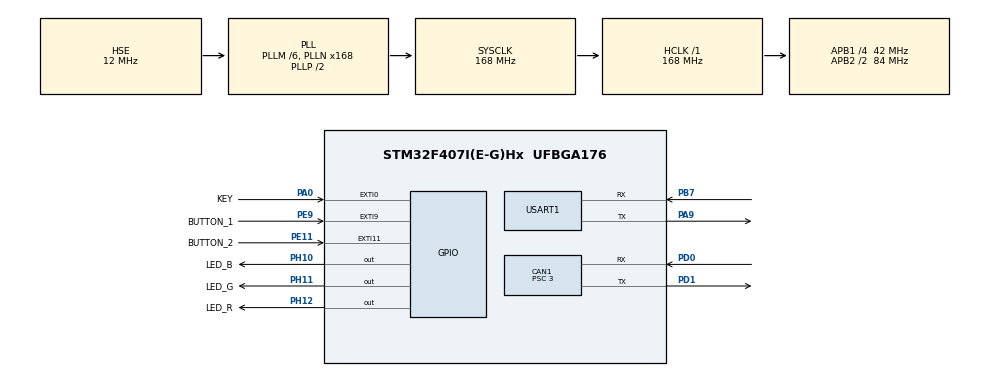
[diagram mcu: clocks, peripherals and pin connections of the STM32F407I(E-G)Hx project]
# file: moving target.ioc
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CAN1.BS1=CAN_BS1_9TQ
CAN1.BS2=CAN_BS2_4TQ
CAN1.CalculateBaudRate=1000000
CAN1.CalculateTimeBit=1000
CAN1.CalculateTimeQuantum=71.42857142857143
CAN1.Prescaler=3
Dma.Request0=USART1_RX
Dma.Request1=USART1_TX
Dma.USART1_RX.0.Direction=DMA_PERIPH_TO_MEMORY
Dma.USART1_RX.0.FIFOMode=DMA_FIFOMODE_DISABLE
Dma.USART1_RX.0.Instance=DMA2_Stream2
Dma.USART1_RX.0.MemDataAlignment=DMA_MDATAALIGN_BYTE
Dma.USART1_RX.0.MemInc=DMA_MINC_ENABLE
Dma.USART1_RX.0.Mode=DMA_NORMAL
Dma.USART1_RX.0.PeriphDataAlignment=DMA_PDATAALIGN_BYTE
Dma.USART1_RX.0.PeriphInc=DMA_PINC_DISABLE
Dma.USART1_RX.0.Priority=DMA_PRIORITY_HIGH
Dma.USART1_TX.1.Direction=DMA_MEMORY_TO_PERIPH
Dma.USART1_TX.1.FIFOMode=DMA_FIFOMODE_DISABLE
Dma.USART1_TX.1.Instance=DMA2_Stream7
Dma.USART1_TX.1.MemDataAlignment=DMA_MDATAALIGN_BYTE
Dma.USART1_TX.1.MemInc=DMA_MINC_ENABLE
Dma.USART1_TX.1.Mode=DMA_NORMAL
Dma.USART1_TX.1.PeriphDataAlignment=DMA_PDATAALIGN_BYTE
Dma.USART1_TX.1.PeriphInc=DMA_PINC_DISABLE
Dma.USART1_TX.1.Priority=DMA_PRIORITY_HIGH
Mcu.Family=STM32F4
Mcu.Name=STM32F407I(E-G)Hx
Mcu.Package=UFBGA176
NVIC.CAN1_RX0_IRQn=true\:0\:0\:false\:false\:true\:true\:true\:true
NVIC.CAN1_TX_IRQn=true\:0\:0\:false\:false\:true\:true\:true\:true
NVIC.DMA2_Stream2_IRQn=true\:0\:0\:false\:false\:true\:false\:true\:true
NVIC.DMA2_Stream7_IRQn=true\:0\:0\:false\:false\:true\:false\:true\:true
NVIC.EXTI0_IRQn=true\:0\:0\:false\:false\:true\:true\:true\:true
NVIC.EXTI15_10_IRQn=true\:1\:0\:true\:false\:true\:true\:true\:true
NVIC.EXTI9_5_IRQn=true\:1\:0\:true\:false\:true\:true\:true\:true
NVIC.PriorityGroup=NVIC_PRIORITYGROUP_4
NVIC.TIM1_BRK_TIM9_IRQn=true\:5\:0\:true\:false\:true\:true\:true\:true
NVIC.TIM1_CC_IRQn=true\:5\:0\:true\:false\:true\:true\:true\:true
NVIC.TIM1_TRG_COM_TIM11_IRQn=true\:5\:0\:true\:false\:true\:true\:true\:true
NVIC.TIM1_UP_TIM10_IRQn=true\:5\:0\:true\:false\:true\:true\:true\:true
NVIC.USART1_IRQn=true\:0\:0\:false\:false\:true\:true\:true\:true
PA0-WKUP.GPIO_Label=KEY
PA0-WKUP.GPIO_ModeDefaultEXTI=GPIO_MODE_IT_FALLING
PA0-WKUP.Signal=GPXTI0
PA13.Mode=Serial_Wire
PA13.Signal=SYS_JTMS-SWDIO
PA14.Mode=Serial_Wire
PA14.Signal=SYS_JTCK-SWCLK
PA9.Mode=Asynchronous
PA9.Signal=USART1_TX
PB7.Mode=Asynchronous
PB7.Signal=USART1_RX
PD0.Mode=CAN_Activate
PD0.Signal=CAN1_RX
PD1.Mode=CAN_Activate
PD1.Signal=CAN1_TX
PE11.GPIO_Label=BUTTON_2
PE11.GPIO_ModeDefaultEXTI=GPIO_MODE_IT_RISING
PE11.GPIO_PuPd=GPIO_PULLDOWN
PE11.Signal=GPXTI11
PE9.GPIO_Label=BUTTON_1
PE9.GPIO_ModeDefaultEXTI=GPIO_MODE_IT_RISING
PE9.GPIO_PuPd=GPIO_PULLDOWN
PE9.Signal=GPXTI9
PH0-OSC_IN.Mode=HSE-External-Oscillator
PH0-OSC_IN.Signal=RCC_OSC_IN
PH1-OSC_OUT.Mode=HSE-External-Oscillator
PH1-OSC_OUT.Signal=RCC_OSC_OUT
PH10.GPIO_Label=LED_B
PH10.Signal=GPIO_Output
PH11.GPIO_Label=LED_G
PH11.Signal=GPIO_Output
PH12.GPIO_Label=LED_R
PH12.Signal=GPIO_Output
ProjectManager.HeapSize=0x200
ProjectManager.StackSize=0x400
ProjectManager.TargetToolchain=CMake
RCC.48MHZClocksFreq_Value=84000000
RCC.AHBFreq_Value=168000000
RCC.APB1CLKDivider=RCC_HCLK_DIV4
RCC.APB1Freq_Value=42000000
RCC.APB1TimFreq_Value=84000000
RCC.APB2CLKDivider=RCC_HCLK_DIV2
RCC.APB2Freq_Value=84000000
RCC.APB2TimFreq_Value=168000000
RCC.CortexFreq_Value=168000000
RCC.HCLKFreq_Value=168000000
RCC.HSE_VALUE=12000000
RCC.HSI_VALUE=16000000
RCC.LSE_VALUE=32768
RCC.PLLM=6
RCC.PLLN=168
RCC.PLLSourceVirtual=RCC_PLLSOURCE_HSE
RCC.SYSCLKFreq_VALUE=168000000
RCC.SYSCLKSource=RCC_SYSCLKSOURCE_PLLCLK
RCC.VCOOutputFreq_Value=336000000
TIM1.Period=1000-1
TIM1.Prescaler=168-1
TIM2.Prescaler=84-1
USART1.VirtualMode=VM_ASYNC
VP_TIM1_VS_ClockSourceINT.Mode=Internal
VP_TIM2_VS_ClockSourceINT.Mode=Internal
board=custom

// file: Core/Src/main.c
/* USER CODE BEGIN Header */
/**
 ******************************************************************************
 * @file           : main.c
 * @brief          : Main program body
 ******************************************************************************
 * @attention
 *
 * Copyright (c) 2024 STMicroelectronics.
 * All rights reserved.
 *
 * This software is licensed under terms that can be found in the LICENSE file
 * in the root directory of this software component.
 * If no LICENSE file comes with this software, it is provided AS-IS.
 *
 ******************************************************************************
 */
/* USER CODE END Header */
#include "main.h"
#include "can.h"
#include "dma.h"
#include "tim.h"
#include "usart.h"
#include "gpio.h"

/* USER CODE BEGIN Includes */

#include "../../../src/entrypoint.hpp"

/* USER CODE END Includes */

void SystemClock_Config(void);

int main(void)
{

  /* MCU Configuration--------------------------------------------------------*/

  /* Reset of all peripherals, Initializes the Flash interface and the Systick. */
  HAL_Init();

  /* Configure the system clock */
  SystemClock_Config();

  /* Initialize all configured peripherals */
  MX_GPIO_Init();
  MX_DMA_Init();
  MX_CAN1_Init();
  MX_USART1_UART_Init();
  MX_TIM1_Init();
  MX_TIM2_Init();
  /* USER CODE BEGIN 2 */

    entrypoint();

  /* USER CODE END 2 */

  /* Infinite loop */
    while (1) {

    }
}

void SystemClock_Config(void)
{
  RCC_OscInitTypeDef RCC_OscInitStruct = {0};
  RCC_ClkInitTypeDef RCC_ClkInitStruct = {0};

  /** Configure the main internal regulator output voltage
  */
  __HAL_RCC_PWR_CLK_ENABLE();
  __HAL_PWR_VOLTAGESCALING_CONFIG(PWR_REGULATOR_VOLTAGE_SCALE1);

  /** Initializes the RCC Oscillators according to the specified parameters
  * in the RCC_OscInitTypeDef structure.
  */
  RCC_OscInitStruct.OscillatorType = RCC_OSCILLATORTYPE_HSE;
  RCC_OscInitStruct.HSEState = RCC_HSE_ON;
  RCC_OscInitStruct.PLL.PLLState = RCC_PLL_ON;
  RCC_OscInitStruct.PLL.PLLSource = RCC_PLLSOURCE_HSE;
  RCC_OscInitStruct.PLL.PLLM = 6;
  RCC_OscInitStruct.PLL.PLLN = 168;
  RCC_OscInitStruct.PLL.PLLP = RCC_PLLP_DIV2;
  RCC_OscInitStruct.PLL.PLLQ = 4;
  if (HAL_RCC_OscConfig(&RCC_OscInitStruct) != HAL_OK)
  {
    Error_Handler();
  }

  /** Initializes the CPU, AHB and APB buses clocks
  */
  RCC_ClkInitStruct.ClockType = RCC_CLOCKTYPE_HCLK|RCC_CLOCKTYPE_SYSCLK
                              |RCC_CLOCKTYPE_PCLK1|RCC_CLOCKTYPE_PCLK2;
  RCC_ClkInitStruct.SYSCLKSource = RCC_SYSCLKSOURCE_PLLCLK;
  RCC_ClkInitStruct.AHBCLKDivider = RCC_SYSCLK_DIV1;
  RCC_ClkInitStruct.APB1CLKDivider = RCC_HCLK_DIV4;
  RCC_ClkInitStruct.APB2CLKDivider = RCC_HCLK_DIV2;

  if (HAL_RCC_ClockConfig(&RCC_ClkInitStruct, FLASH_LATENCY_5) != HAL_OK)
  {
    Error_Handler();
  }
}

void Error_Handler(void)
{
    __disable_irq();
    while (1) {
    }
}
